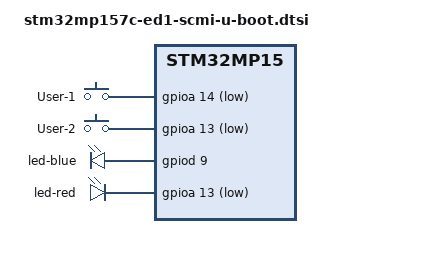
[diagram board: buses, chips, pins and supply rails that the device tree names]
// SPDX-License-Identifier: GPL-2.0-or-later OR BSD-3-Clause
/*
 * Copyright : STMicroelectronics 2022
 */

#include <dt-bindings/input/linux-event-codes.h>
#include "stm32mp15-scmi-u-boot.dtsi"

/ {
	aliases {
		i2c3 = &i2c4;
	};

	config {
		u-boot,boot-led = "led-blue";
		u-boot,error-led = "led-red";
		u-boot,mmc-env-partition = "u-boot-env";
	};

	gpio-keys {
		compatible = "gpio-keys";

		button-user-1 {
			label = "User-1";
			linux,code = <BTN_1>;
			gpios = <&gpioa 14 (GPIO_ACTIVE_LOW | GPIO_PULL_UP)>;
		};

		button-user-2 {
			label = "User-2";
			linux,code = <BTN_2>;
			gpios = <&gpioa 13 (GPIO_ACTIVE_LOW | GPIO_PULL_UP)>;
		};
	};

	led {
		compatible = "gpio-leds";

		led-blue {
			gpios = <&gpiod 9 GPIO_ACTIVE_HIGH>;
		};

		led-red {
			gpios = <&gpioa 13 GPIO_ACTIVE_LOW>;
		};
	};
};

&uart4 {
	bootph-all;
};

&uart4_pins_a {
	bootph-all;
	pins1 {
		bootph-all;
	};
	pins2 {
		bootph-all;
		/* pull-up on rx to avoid floating level */
		bias-pull-up;
	};
};
